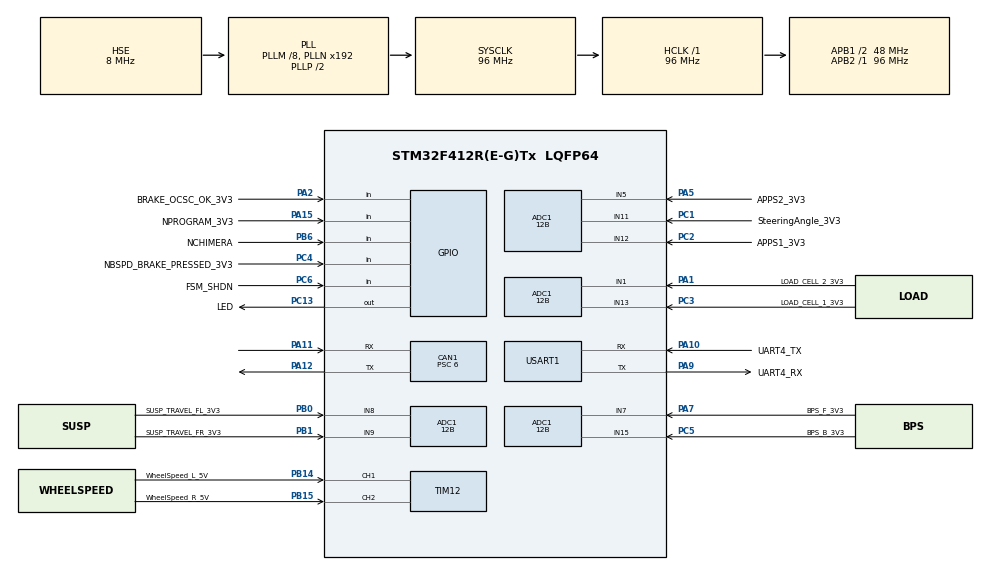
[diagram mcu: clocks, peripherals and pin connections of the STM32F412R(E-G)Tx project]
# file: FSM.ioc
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ADC1.Channel-0\#ChannelRegularConversion=ADC_CHANNEL_1
ADC1.Channel-1\#ChannelRegularConversion=ADC_CHANNEL_5
ADC1.Channel-2\#ChannelRegularConversion=ADC_CHANNEL_7
ADC1.Channel-3\#ChannelRegularConversion=ADC_CHANNEL_8
ADC1.Channel-4\#ChannelRegularConversion=ADC_CHANNEL_9
ADC1.Channel-5\#ChannelRegularConversion=ADC_CHANNEL_11
ADC1.Channel-6\#ChannelRegularConversion=ADC_CHANNEL_12
ADC1.Channel-7\#ChannelRegularConversion=ADC_CHANNEL_13
ADC1.Channel-8\#ChannelRegularConversion=ADC_CHANNEL_15
ADC1.DMAContinuousRequests=ENABLE
ADC1.ExternalTrigConv=ADC_EXTERNALTRIGCONV_T3_TRGO
ADC1.NbrOfConversion=9
ADC1.NbrOfConversionFlag=1
ADC1.Rank-0\#ChannelRegularConversion=1
ADC1.Rank-1\#ChannelRegularConversion=2
ADC1.Rank-2\#ChannelRegularConversion=3
ADC1.Rank-3\#ChannelRegularConversion=4
ADC1.Rank-4\#ChannelRegularConversion=5
ADC1.Rank-5\#ChannelRegularConversion=6
ADC1.Rank-6\#ChannelRegularConversion=7
ADC1.Rank-7\#ChannelRegularConversion=8
ADC1.Rank-8\#ChannelRegularConversion=9
ADC1.Resolution=ADC_RESOLUTION_12B
ADC1.SamplingTime-0\#ChannelRegularConversion=ADC_SAMPLETIME_3CYCLES
ADC1.SamplingTime-1\#ChannelRegularConversion=ADC_SAMPLETIME_3CYCLES
ADC1.SamplingTime-2\#ChannelRegularConversion=ADC_SAMPLETIME_3CYCLES
ADC1.SamplingTime-3\#ChannelRegularConversion=ADC_SAMPLETIME_3CYCLES
ADC1.SamplingTime-4\#ChannelRegularConversion=ADC_SAMPLETIME_3CYCLES
ADC1.SamplingTime-5\#ChannelRegularConversion=ADC_SAMPLETIME_3CYCLES
ADC1.SamplingTime-6\#ChannelRegularConversion=ADC_SAMPLETIME_3CYCLES
ADC1.SamplingTime-7\#ChannelRegularConversion=ADC_SAMPLETIME_3CYCLES
ADC1.SamplingTime-8\#ChannelRegularConversion=ADC_SAMPLETIME_3CYCLES
ADC1.master=1
CAN1.ABOM=ENABLE
CAN1.BS1=CAN_BS1_12TQ
CAN1.BS2=CAN_BS2_3TQ
CAN1.CalculateBaudRate=500000
CAN1.CalculateTimeBit=2000
CAN1.CalculateTimeQuantum=125.0
CAN1.NART=ENABLE
CAN1.Prescaler=6
CAN1.RFLM=ENABLE
CAN1.SJW=CAN_SJW_3TQ
CAN1.TXFP=ENABLE
Dma.ADC1.0.Direction=DMA_PERIPH_TO_MEMORY
Dma.ADC1.0.FIFOMode=DMA_FIFOMODE_DISABLE
Dma.ADC1.0.Instance=DMA2_Stream0
Dma.ADC1.0.MemDataAlignment=DMA_MDATAALIGN_HALFWORD
Dma.ADC1.0.MemInc=DMA_MINC_ENABLE
Dma.ADC1.0.Mode=DMA_CIRCULAR
Dma.ADC1.0.PeriphDataAlignment=DMA_PDATAALIGN_HALFWORD
Dma.ADC1.0.PeriphInc=DMA_PINC_DISABLE
Dma.ADC1.0.Priority=DMA_PRIORITY_LOW
Dma.Request0=ADC1
FREERTOS.Tasks01=Task1kHz,48,512,StartTask1kHz,Default,NULL,Static,Task1kHzBuffer,Task1kHzControlBlock;Task100Hz,40,512,RunTask100Hz,Default,NULL,Static,Task100HzBuffer,Task100HzControlBlock;TaskCanRx,24,512,RunTaskCanRx,Default,NULL,Static,TaskCanRxBuffer,TaskCanRxControlBlock;TaskCanTx,24,512,RunTaskCanTx,Default,NULL,Static,TaskCanTxBuffer,TaskCanTxControlBlock;Task1Hz,32,512,RunTask1Hz,Default,NULL,Static,Task1HzBuffer,Task1HzControlBlock
IWDG.Reload=LSI_FREQUENCY /  IWDG_PRESCALER / IWDG_RESET_FREQUENCY
Mcu.Family=STM32F4
Mcu.Name=STM32F412R(E-G)Tx
Mcu.Package=LQFP64
Mcu.UserConstants=TASK_100HZ_STACK_SIZE,512;TASK_CANRX_STACK_SIZE,512;TASK_CANTX_STACK_SIZE,512;TIM3_PRESCALER,8;TIM12_PWM_MINIMUM_FREQUENCY,1;ADC_FREQUENCY,1000;TIMx_FREQUENCY,96000000;IWDG_RESET_FREQUENCY,5;TIM12_PRESCALER,(TIMx_FREQUENCY / TIM12_AUTO_RELOAD_REG / TIM12_PWM_MINIMUM_FREQUENCY);TASK_1HZ_STACK_SIZE,512;TASK_1KHZ_STACK_SIZE,512;TIM12_AUTO_RELOAD_REG,0xFFFF;IWDG_PRESCALER,4;IWDG_WINDOW_DISABLE_VALUE,4095;LSI_FREQUENCY,32000;TIM4_PRESCALAR,8
NVIC.CAN1_RX0_IRQn=true\:5\:0\:false\:false\:true\:true\:true\:true\:true
NVIC.CAN1_RX1_IRQn=true\:5\:0\:false\:false\:true\:true\:true\:true\:true
NVIC.DMA2_Stream0_IRQn=true\:5\:0\:false\:false\:true\:true\:false\:true\:true
NVIC.PriorityGroup=NVIC_PRIORITYGROUP_4
NVIC.TIM3_IRQn=true\:5\:0\:false\:false\:true\:true\:true\:true\:true
NVIC.TIM6_IRQn=true\:15\:0\:false\:false\:true\:false\:false\:true\:true
NVIC.TIM8_BRK_TIM12_IRQn=true\:5\:0\:false\:false\:true\:true\:true\:true\:true
NVIC.TimeBase=TIM6_IRQn
NVIC.TimeBaseIP=TIM6
NVIC.USART1_IRQn=true\:5\:0\:false\:false\:true\:true\:true\:true\:true
PA1.GPIO_Label=LOAD_CELL_2_3V3
PA1.Signal=ADCx_IN1
PA10.GPIO_Label=UART4_TX
PA10.Mode=Asynchronous
PA10.Signal=USART1_RX
PA11.Mode=CAN_Activate
PA11.Signal=CAN1_RX
PA12.Mode=CAN_Activate
PA12.Signal=CAN1_TX
PA13.Mode=Trace_Asynchronous_SW
PA13.Signal=SYS_JTMS-SWDIO
PA14.Mode=Trace_Asynchronous_SW
PA14.Signal=SYS_JTCK-SWCLK
PA15.GPIO_Label=NPROGRAM_3V3
PA15.GPIO_PuPd=GPIO_PULLUP
PA15.Signal=GPIO_Input
PA2.GPIO_Label=BRAKE_OCSC_OK_3V3
PA2.GPIO_PuPd=GPIO_NOPULL
PA2.Signal=GPIO_Input
PA5.GPIO_Label=APPS2_3V3
PA5.Signal=ADCx_IN5
PA7.GPIO_Label=BPS_F_3V3
PA7.Signal=ADCx_IN7
PA9.GPIO_Label=UART4_RX
PA9.Mode=Asynchronous
PA9.Signal=USART1_TX
PB0.GPIO_Label=SUSP_TRAVEL_FL_3V3
PB0.Signal=ADCx_IN8
PB1.GPIO_Label=SUSP_TRAVEL_FR_3V3
PB1.Signal=ADCx_IN9
PB14.GPIO_Label=WheelSpeed_L_5V
PB14.Signal=S_TIM12_CH1
PB15.GPIO_Label=WheelSpeed_R_5V
PB15.Signal=S_TIM12_CH2
PB3.Mode=Trace_Asynchronous_SW
PB3.Signal=SYS_JTDO-SWO
PB6.GPIO_Label=NCHIMERA
PB6.GPIO_PuPd=GPIO_PULLUP
PB6.Signal=GPIO_Input
PC1.GPIO_Label=SteeringAngle_3V3
PC1.Signal=ADCx_IN11
PC13.GPIO_Label=LED
PC13.Signal=GPIO_Output
PC2.GPIO_Label=APPS1_3V3
PC2.Signal=ADCx_IN12
PC3.GPIO_Label=LOAD_CELL_1_3V3
PC3.Signal=ADCx_IN13
PC4.GPIO_Label=NBSPD_BRAKE_PRESSED_3V3
PC4.Signal=GPIO_Input
PC5.GPIO_Label=BPS_B_3V3
PC5.Signal=ADCx_IN15
PC6.GPIO_Label=FSM_SHDN
PC6.Signal=GPIO_Input
PH0\ -\ OSC_IN.Mode=HSE-External-Oscillator
PH0\ -\ OSC_IN.Signal=RCC_OSC_IN
PH1\ -\ OSC_OUT.Mode=HSE-External-Oscillator
PH1\ -\ OSC_OUT.Signal=RCC_OSC_OUT
ProjectManager.HeapSize=0x00
ProjectManager.StackSize=0x400
ProjectManager.TargetToolchain=STM32CubeIDE
RCC.AHBFreq_Value=96000000
RCC.APB1CLKDivider=RCC_HCLK_DIV2
RCC.APB1Freq_Value=48000000
RCC.APB1TimFreq_Value=96000000
RCC.APB2Freq_Value=96000000
RCC.APB2TimFreq_Value=96000000
RCC.CortexFreq_Value=96000000
RCC.HCLKFreq_Value=96000000
RCC.HSE_VALUE=8000000
RCC.PLLM=8
RCC.PLLSourceVirtual=RCC_PLLSOURCE_HSE
RCC.SYSCLKFreq_VALUE=96000000
RCC.SYSCLKSource=RCC_SYSCLKSOURCE_PLLCLK
RCC.USBFreq_Value=96000000
RCC.VCOOutputFreq_Value=192000000
SH.ADCx_IN1.0=ADC1_IN1,IN1
SH.ADCx_IN11.0=ADC1_IN11,IN11
SH.ADCx_IN12.0=ADC1_IN12,IN12
SH.ADCx_IN13.0=ADC1_IN13,IN13
SH.ADCx_IN15.0=ADC1_IN15,IN15
SH.ADCx_IN5.0=ADC1_IN5,IN5
SH.ADCx_IN7.0=ADC1_IN7,IN7
SH.ADCx_IN8.0=ADC1_IN8,IN8
SH.ADCx_IN9.0=ADC1_IN9,IN9
SH.S_TIM12_CH1.0=TIM12_CH1,Input_Capture1_from_TI1
SH.S_TIM12_CH2.0=TIM12_CH2,Input_Capture2_from_TI2
TIM12.Channel-Input_Capture1_from_TI1=TIM_CHANNEL_1
TIM12.Channel-Input_Capture2_from_TI2=TIM_CHANNEL_2
TIM3.Period=(TIMx_FREQUENCY / TIM3_PRESCALER / ADC_FREQUENCY) - 1
TIM3.Prescaler=TIM3_PRESCALER - 1 
TIM3.TIM_MasterOutputTrigger=TIM_TRGO_UPDATE
USART1.VirtualMode=VM_ASYNC
VP_FREERTOS_VS_CMSIS_V2.Mode=CMSIS_V2
VP_IWDG_VS_IWDG.Mode=IWDG_Activate
VP_SYS_VS_tim6.Mode=TIM6
VP_TIM3_VS_ClockSourceINT.Mode=Internal
board=custom

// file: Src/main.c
/* USER CODE BEGIN Header */
/**
 ******************************************************************************
 * @file           : main.c
 * @brief          : Main program body
 ******************************************************************************
 * @attention
 *
 * Copyright (c) 2024 STMicroelectronics.
 * All rights reserved.
 *
 * This software is licensed under terms that can be found in the LICENSE file
 * in the root directory of this software component.
 * If no LICENSE file comes with this software, it is provided AS-IS.
 *
 ******************************************************************************
 */
/* USER CODE END Header */
#include "main.h"
#include "cmsis_os.h"

/* USER CODE BEGIN Includes */
#include "tasks.h"
#include "hw_error.h"
/* USER CODE END Includes */

typedef StaticTask_t osStaticThreadDef_t;

ADC_HandleTypeDef hadc1;
DMA_HandleTypeDef hdma_adc1;

CAN_HandleTypeDef hcan1;

IWDG_HandleTypeDef hiwdg;

TIM_HandleTypeDef htim3;
TIM_HandleTypeDef htim12;

UART_HandleTypeDef huart1;

/* Definitions for Task1kHz */
osThreadId_t         Task1kHzHandle;
uint32_t             Task1kHzBuffer[512];
osStaticThreadDef_t  Task1kHzControlBlock;
const osThreadAttr_t Task1kHz_attributes = {
    .name       = "Task1kHz",
    .cb_mem     = &Task1kHzControlBlock,
    .cb_size    = sizeof(Task1kHzControlBlock),
    .stack_mem  = &Task1kHzBuffer[0],
    .stack_size = sizeof(Task1kHzBuffer),
    .priority   = (osPriority_t)osPriorityRealtime,
};
/* Definitions for Task100Hz */
osThreadId_t         Task100HzHandle;
uint32_t             Task100HzBuffer[512];
osStaticThreadDef_t  Task100HzControlBlock;
const osThreadAttr_t Task100Hz_attributes = {
    .name       = "Task100Hz",
    .cb_mem     = &Task100HzControlBlock,
    .cb_size    = sizeof(Task100HzControlBlock),
    .stack_mem  = &Task100HzBuffer[0],
    .stack_size = sizeof(Task100HzBuffer),
    .priority   = (osPriority_t)osPriorityHigh,
};
/* Definitions for TaskCanRx */
osThreadId_t         TaskCanRxHandle;
uint32_t             TaskCanRxBuffer[512];
osStaticThreadDef_t  TaskCanRxControlBlock;
const osThreadAttr_t TaskCanRx_attributes = {
    .name       = "TaskCanRx",
    .cb_mem     = &TaskCanRxControlBlock,
    .cb_size    = sizeof(TaskCanRxControlBlock),
    .stack_mem  = &TaskCanRxBuffer[0],
    .stack_size = sizeof(TaskCanRxBuffer),
    .priority   = (osPriority_t)osPriorityNormal,
};
/* Definitions for TaskCanTx */
osThreadId_t         TaskCanTxHandle;
uint32_t             TaskCanTxBuffer[512];
osStaticThreadDef_t  TaskCanTxControlBlock;
const osThreadAttr_t TaskCanTx_attributes = {
    .name       = "TaskCanTx",
    .cb_mem     = &TaskCanTxControlBlock,
    .cb_size    = sizeof(TaskCanTxControlBlock),
    .stack_mem  = &TaskCanTxBuffer[0],
    .stack_size = sizeof(TaskCanTxBuffer),
    .priority   = (osPriority_t)osPriorityNormal,
};
/* Definitions for Task1Hz */
osThreadId_t         Task1HzHandle;
uint32_t             Task1HzBuffer[512];
osStaticThreadDef_t  Task1HzControlBlock;
const osThreadAttr_t Task1Hz_attributes = {
    .name       = "Task1Hz",
    .cb_mem     = &Task1HzControlBlock,
    .cb_size    = sizeof(Task1HzControlBlock),
    .stack_mem  = &Task1HzBuffer[0],
    .stack_size = sizeof(Task1HzBuffer),
    .priority   = (osPriority_t)osPriorityAboveNormal,
};

void        SystemClock_Config(void);
static void MX_GPIO_Init(void);
static void MX_DMA_Init(void);
static void MX_ADC1_Init(void);
static void MX_CAN1_Init(void);
static void MX_TIM12_Init(void);
static void MX_USART1_UART_Init(void);
static void MX_TIM3_Init(void);
static void MX_IWDG_Init(void);
void        StartTask1kHz(void *argument);
void        RunTask100Hz(void *argument);
void        RunTaskCanRx(void *argument);
void        RunTaskCanTx(void *argument);
void        RunTask1Hz(void *argument);

int main(void)
{
    /* USER CODE BEGIN 1 */
    tasks_preInit();
    /* USER CODE END 1 */

    /* MCU Configuration--------------------------------------------------------*/

    /* Reset of all peripherals, Initializes the Flash interface and the Systick. */
    HAL_Init();

    /* Configure the system clock */
    SystemClock_Config();

    /* Initialize all configured peripherals */
    MX_GPIO_Init();
    MX_DMA_Init();
    MX_ADC1_Init();
    MX_CAN1_Init();
    MX_TIM12_Init();
    MX_USART1_UART_Init();
    MX_TIM3_Init();
    MX_IWDG_Init();
    /* USER CODE BEGIN 2 */

    tasks_init();

    /* USER CODE END 2 */

    /* Init scheduler */
    osKernelInitialize();

    /* Create the thread(s) */
    /* creation of Task1kHz */
    Task1kHzHandle = osThreadNew(StartTask1kHz, NULL, &Task1kHz_attributes);

    /* creation of Task100Hz */
    Task100HzHandle = osThreadNew(RunTask100Hz, NULL, &Task100Hz_attributes);

    /* creation of TaskCanRx */
    TaskCanRxHandle = osThreadNew(RunTaskCanRx, NULL, &TaskCanRx_attributes);

    /* creation of TaskCanTx */
    TaskCanTxHandle = osThreadNew(RunTaskCanTx, NULL, &TaskCanTx_attributes);

    /* creation of Task1Hz */
    Task1HzHandle = osThreadNew(RunTask1Hz, NULL, &Task1Hz_attributes);

    /* Start scheduler */
    osKernelStart();

    /* We should never get here as control is now taken by the scheduler */
    /* Infinite loop */
    while (1)
    {

    }
}

void SystemClock_Config(void)
{
    RCC_OscInitTypeDef RCC_OscInitStruct = { 0 };
    RCC_ClkInitTypeDef RCC_ClkInitStruct = { 0 };

    /** Configure the main internal regulator output voltage
     */
    __HAL_RCC_PWR_CLK_ENABLE();
    __HAL_PWR_VOLTAGESCALING_CONFIG(PWR_REGULATOR_VOLTAGE_SCALE1);

    /** Initializes the RCC Oscillators according to the specified parameters
     * in the RCC_OscInitTypeDef structure.
     */
    RCC_OscInitStruct.OscillatorType = RCC_OSCILLATORTYPE_LSI | RCC_OSCILLATORTYPE_HSE;
    RCC_OscInitStruct.HSEState       = RCC_HSE_ON;
    RCC_OscInitStruct.LSIState       = RCC_LSI_ON;
    RCC_OscInitStruct.PLL.PLLState   = RCC_PLL_ON;
    RCC_OscInitStruct.PLL.PLLSource  = RCC_PLLSOURCE_HSE;
    RCC_OscInitStruct.PLL.PLLM       = 8;
    RCC_OscInitStruct.PLL.PLLN       = 192;
    RCC_OscInitStruct.PLL.PLLP       = RCC_PLLP_DIV2;
    RCC_OscInitStruct.PLL.PLLQ       = 2;
    RCC_OscInitStruct.PLL.PLLR       = 2;
    if (HAL_RCC_OscConfig(&RCC_OscInitStruct) != HAL_OK)
    {
        Error_Handler();
    }

    /** Initializes the CPU, AHB and APB buses clocks
     */
    RCC_ClkInitStruct.ClockType = RCC_CLOCKTYPE_HCLK | RCC_CLOCKTYPE_SYSCLK | RCC_CLOCKTYPE_PCLK1 | RCC_CLOCKTYPE_PCLK2;
    RCC_ClkInitStruct.SYSCLKSource   = RCC_SYSCLKSOURCE_PLLCLK;
    RCC_ClkInitStruct.AHBCLKDivider  = RCC_SYSCLK_DIV1;
    RCC_ClkInitStruct.APB1CLKDivider = RCC_HCLK_DIV2;
    RCC_ClkInitStruct.APB2CLKDivider = RCC_HCLK_DIV1;

    if (HAL_RCC_ClockConfig(&RCC_ClkInitStruct, FLASH_LATENCY_3) != HAL_OK)
    {
        Error_Handler();
    }
}

static void MX_ADC1_Init(void)
{

    ADC_ChannelConfTypeDef sConfig = { 0 };

    /** Configure the global features of the ADC (Clock, Resolution, Data Alignment and number of conversion)
     */
    hadc1.Instance                   = ADC1;
    hadc1.Init.ClockPrescaler        = ADC_CLOCK_SYNC_PCLK_DIV4;
    hadc1.Init.Resolution            = ADC_RESOLUTION_12B;
    hadc1.Init.ScanConvMode          = ENABLE;
    hadc1.Init.ContinuousConvMode    = DISABLE;
    hadc1.Init.DiscontinuousConvMode = DISABLE;
    hadc1.Init.ExternalTrigConvEdge  = ADC_EXTERNALTRIGCONVEDGE_RISING;
    hadc1.Init.ExternalTrigConv      = ADC_EXTERNALTRIGCONV_T3_TRGO;
    hadc1.Init.DataAlign             = ADC_DATAALIGN_RIGHT;
    hadc1.Init.NbrOfConversion       = 9;
    hadc1.Init.DMAContinuousRequests = ENABLE;
    hadc1.Init.EOCSelection          = ADC_EOC_SINGLE_CONV;
    if (HAL_ADC_Init(&hadc1) != HAL_OK)
    {
        Error_Handler();
    }

    /** Configure for the selected ADC regular channel its corresponding rank in the sequencer and its sample time.
     */
    sConfig.Channel      = ADC_CHANNEL_1;
    sConfig.Rank         = 1;
    sConfig.SamplingTime = ADC_SAMPLETIME_3CYCLES;
    if (HAL_ADC_ConfigChannel(&hadc1, &sConfig) != HAL_OK)
    {
        Error_Handler();
    }

    /** Configure for the selected ADC regular channel its corresponding rank in the sequencer and its sample time.
     */
    sConfig.Channel = ADC_CHANNEL_5;
    sConfig.Rank    = 2;
    if (HAL_ADC_ConfigChannel(&hadc1, &sConfig) != HAL_OK)
    {
        Error_Handler();
    }

    /** Configure for the selected ADC regular channel its corresponding rank in the sequencer and its sample time.
     */
    sConfig.Channel = ADC_CHANNEL_7;
    sConfig.Rank    = 3;
    if (HAL_ADC_ConfigChannel(&hadc1, &sConfig) != HAL_OK)
    {
        Error_Handler();
    }

    /** Configure for the selected ADC regular channel its corresponding rank in the sequencer and its sample time.
     */
    sConfig.Channel = ADC_CHANNEL_8;
    sConfig.Rank    = 4;
    if (HAL_ADC_ConfigChannel(&hadc1, &sConfig) != HAL_OK)
    {
        Error_Handler();
    }

    /** Configure for the selected ADC regular channel its corresponding rank in the sequencer and its sample time.
     */
    sConfig.Channel = ADC_CHANNEL_9;
    sConfig.Rank    = 5;
    if (HAL_ADC_ConfigChannel(&hadc1, &sConfig) != HAL_OK)
    {
        Error_Handler();
    }

    /** Configure for the selected ADC regular channel its corresponding rank in the sequencer and its sample time.
     */
    sConfig.Channel = ADC_CHANNEL_11;
    sConfig.Rank    = 6;
    if (HAL_ADC_ConfigChannel(&hadc1, &sConfig) != HAL_OK)
    {
        Error_Handler();
    }

    /** Configure for the selected ADC regular channel its corresponding rank in the sequencer and its sample time.
     */
    sConfig.Channel = ADC_CHANNEL_12;
    sConfig.Rank    = 7;
    if (HAL_ADC_ConfigChannel(&hadc1, &sConfig) != HAL_OK)
    {
        Error_Handler();
    }

    /** Configure for the selected ADC regular channel its corresponding rank in the sequencer and its sample time.
     */
    sConfig.Channel = ADC_CHANNEL_13;
    sConfig.Rank    = 8;
    if (HAL_ADC_ConfigChannel(&hadc1, &sConfig) != HAL_OK)
    {
        Error_Handler();
    }

    /** Configure for the selected ADC regular channel its corresponding rank in the sequencer and its sample time.
     */
    sConfig.Channel = ADC_CHANNEL_15;
    sConfig.Rank    = 9;
    if (HAL_ADC_ConfigChannel(&hadc1, &sConfig) != HAL_OK)
    {
        Error_Handler();
    }
}

static void MX_CAN1_Init(void)
{

    hcan1.Instance                  = CAN1;
    hcan1.Init.Prescaler            = 6;
    hcan1.Init.Mode                 = CAN_MODE_NORMAL;
    hcan1.Init.SyncJumpWidth        = CAN_SJW_3TQ;
    hcan1.Init.TimeSeg1             = CAN_BS1_12TQ;
    hcan1.Init.TimeSeg2             = CAN_BS2_3TQ;
    hcan1.Init.TimeTriggeredMode    = DISABLE;
    hcan1.Init.AutoBusOff           = ENABLE;
    hcan1.Init.AutoWakeUp           = DISABLE;
    hcan1.Init.AutoRetransmission   = ENABLE;
    hcan1.Init.ReceiveFifoLocked    = ENABLE;
    hcan1.Init.TransmitFifoPriority = ENABLE;
    if (HAL_CAN_Init(&hcan1) != HAL_OK)
    {
        Error_Handler();
    }
}

static void MX_IWDG_Init(void)
{

    hiwdg.Instance       = IWDG;
    hiwdg.Init.Prescaler = IWDG_PRESCALER_4;
    hiwdg.Init.Reload    = LSI_FREQUENCY / IWDG_PRESCALER / IWDG_RESET_FREQUENCY;
    if (HAL_IWDG_Init(&hiwdg) != HAL_OK)
    {
        Error_Handler();
    }
}

static void MX_TIM3_Init(void)
{

    TIM_ClockConfigTypeDef  sClockSourceConfig = { 0 };
    TIM_MasterConfigTypeDef sMasterConfig      = { 0 };

    htim3.Instance               = TIM3;
    htim3.Init.Prescaler         = TIM3_PRESCALER - 1;
    htim3.Init.CounterMode       = TIM_COUNTERMODE_UP;
    htim3.Init.Period            = (TIMx_FREQUENCY / TIM3_PRESCALER / ADC_FREQUENCY) - 1;
    htim3.Init.ClockDivision     = TIM_CLOCKDIVISION_DIV1;
    htim3.Init.AutoReloadPreload = TIM_AUTORELOAD_PRELOAD_DISABLE;
    if (HAL_TIM_Base_Init(&htim3) != HAL_OK)
    {
        Error_Handler();
    }
    sClockSourceConfig.ClockSource = TIM_CLOCKSOURCE_INTERNAL;
    if (HAL_TIM_ConfigClockSource(&htim3, &sClockSourceConfig) != HAL_OK)
    {
        Error_Handler();
    }
    sMasterConfig.MasterOutputTrigger = TIM_TRGO_UPDATE;
    sMasterConfig.MasterSlaveMode     = TIM_MASTERSLAVEMODE_DISABLE;
    if (HAL_TIMEx_MasterConfigSynchronization(&htim3, &sMasterConfig) != HAL_OK)
    {
        Error_Handler();
    }
}

static void MX_TIM12_Init(void)
{

    TIM_IC_InitTypeDef sConfigIC = { 0 };

    htim12.Instance               = TIM12;
    htim12.Init.Prescaler         = 0;
    htim12.Init.CounterMode       = TIM_COUNTERMODE_UP;
    htim12.Init.Period            = 65535;
    htim12.Init.ClockDivision     = TIM_CLOCKDIVISION_DIV1;
    htim12.Init.AutoReloadPreload = TIM_AUTORELOAD_PRELOAD_DISABLE;
    if (HAL_TIM_IC_Init(&htim12) != HAL_OK)
    {
        Error_Handler();
    }
    sConfigIC.ICPolarity  = TIM_INPUTCHANNELPOLARITY_RISING;
    sConfigIC.ICSelection = TIM_ICSELECTION_DIRECTTI;
    sConfigIC.ICPrescaler = TIM_ICPSC_DIV1;
    sConfigIC.ICFilter    = 0;
    if (HAL_TIM_IC_ConfigChannel(&htim12, &sConfigIC, TIM_CHANNEL_1) != HAL_OK)
    {
        Error_Handler();
    }
    if (HAL_TIM_IC_ConfigChannel(&htim12, &sConfigIC, TIM_CHANNEL_2) != HAL_OK)
    {
        Error_Handler();
    }
}

static void MX_USART1_UART_Init(void)
{

    huart1.Instance          = USART1;
    huart1.Init.BaudRate     = 115200;
    huart1.Init.WordLength   = UART_WORDLENGTH_8B;
    huart1.Init.StopBits     = UART_STOPBITS_1;
    huart1.Init.Parity       = UART_PARITY_NONE;
    huart1.Init.Mode         = UART_MODE_TX_RX;
    huart1.Init.HwFlowCtl    = UART_HWCONTROL_NONE;
    huart1.Init.OverSampling = UART_OVERSAMPLING_16;
    if (HAL_UART_Init(&huart1) != HAL_OK)
    {
        Error_Handler();
    }
}

static void MX_DMA_Init(void)
{
    /* DMA controller clock enable */
    __HAL_RCC_DMA2_CLK_ENABLE();

    /* DMA interrupt init */
    /* DMA2_Stream0_IRQn interrupt configuration */
    HAL_NVIC_SetPriority(DMA2_Stream0_IRQn, 5, 0);
    HAL_NVIC_EnableIRQ(DMA2_Stream0_IRQn);
}

static void MX_GPIO_Init(void)
{
    GPIO_InitTypeDef GPIO_InitStruct = { 0 };

    /* GPIO Ports Clock Enable */
    __HAL_RCC_GPIOC_CLK_ENABLE();
    __HAL_RCC_GPIOH_CLK_ENABLE();
    __HAL_RCC_GPIOA_CLK_ENABLE();
    __HAL_RCC_GPIOB_CLK_ENABLE();

    /*Configure GPIO pin Output Level */
    HAL_GPIO_WritePin(LED_GPIO_Port, LED_Pin, GPIO_PIN_RESET);

    /*Configure GPIO pin : LED_Pin */
    GPIO_InitStruct.Pin   = LED_Pin;
    GPIO_InitStruct.Mode  = GPIO_MODE_OUTPUT_PP;
    GPIO_InitStruct.Pull  = GPIO_NOPULL;
    GPIO_InitStruct.Speed = GPIO_SPEED_FREQ_LOW;
    HAL_GPIO_Init(LED_GPIO_Port, &GPIO_InitStruct);

    /*Configure GPIO pin : BRAKE_OCSC_OK_3V3_Pin */
    GPIO_InitStruct.Pin  = BRAKE_OCSC_OK_3V3_Pin;
    GPIO_InitStruct.Mode = GPIO_MODE_INPUT;
    GPIO_InitStruct.Pull = GPIO_NOPULL;
    HAL_GPIO_Init(BRAKE_OCSC_OK_3V3_GPIO_Port, &GPIO_InitStruct);

    /*Configure GPIO pins : NBSPD_BRAKE_PRESSED_3V3_Pin FSM_SHDN_Pin */
    GPIO_InitStruct.Pin  = NBSPD_BRAKE_PRESSED_3V3_Pin | FSM_SHDN_Pin;
    GPIO_InitStruct.Mode = GPIO_MODE_INPUT;
    GPIO_InitStruct.Pull = GPIO_NOPULL;
    HAL_GPIO_Init(GPIOC, &GPIO_InitStruct);

    /*Configure GPIO pin : NPROGRAM_3V3_Pin */
    GPIO_InitStruct.Pin  = NPROGRAM_3V3_Pin;
    GPIO_InitStruct.Mode = GPIO_MODE_INPUT;
    GPIO_InitStruct.Pull = GPIO_PULLUP;
    HAL_GPIO_Init(NPROGRAM_3V3_GPIO_Port, &GPIO_InitStruct);

    /*Configure GPIO pin : NCHIMERA_Pin */
    GPIO_InitStruct.Pin  = NCHIMERA_Pin;
    GPIO_InitStruct.Mode = GPIO_MODE_INPUT;
    GPIO_InitStruct.Pull = GPIO_PULLUP;
    HAL_GPIO_Init(NCHIMERA_GPIO_Port, &GPIO_InitStruct);

}

void StartTask1kHz(void *argument)
{
    /* USER CODE BEGIN 5 */
    /* Infinite loop */
    tasks_run1kHz();
    /* USER CODE END 5 */
}

void RunTask100Hz(void *argument)
{
    /* USER CODE BEGIN RunTask100Hz */
    tasks_run100Hz();
    /* USER CODE END RunTask100Hz */
}

void RunTaskCanRx(void *argument)
{
    /* USER CODE BEGIN RunTaskCanRx */
    tasks_runCanRx();
    /* USER CODE END RunTaskCanRx */
}

void RunTaskCanTx(void *argument)
{
    /* USER CODE BEGIN RunTaskCanTx */
    tasks_runCanTx();
    /* USER CODE END RunTaskCanTx */
}

void RunTask1Hz(void *argument)
{
    /* USER CODE BEGIN RunTask1Hz */
    tasks_run1Hz();
    /* USER CODE END RunTask1Hz */
}

void HAL_TIM_PeriodElapsedCallback(TIM_HandleTypeDef *htim)
{
    if (htim->Instance == TIM6)
    {
        HAL_IncTick();
    }
}

void Error_Handler(void)
{
    __disable_irq();
    while (1)
    {
    }
}
